# CLK2_FLAGMUX_CLK2 register map
Vendor: Texas Instruments
Peripheral module from a debugger description file (folder TDA2Ex).
Registers are 32-bit, read-only, reset values left out (the file's numbers can be read two ways) unless marked. A register's access mark holds for its fields unless they carry their own. Offsets are as the file gives them; lines under a group give offsets from that group; [hi:lo] are bit positions; {n}, {i} and the like mark numbered series; 'fields as' and 'values as' point back to an identical list; <NAME> marks a mode.

## CLK2_FLAGMUX_CLK2
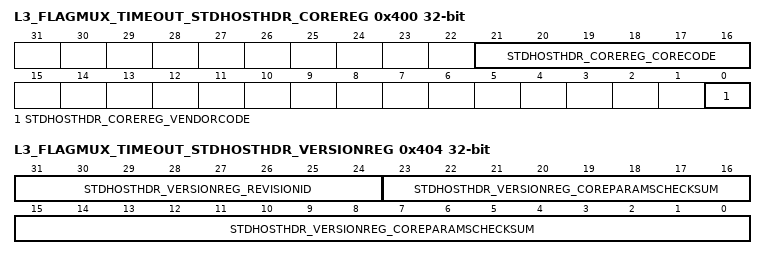
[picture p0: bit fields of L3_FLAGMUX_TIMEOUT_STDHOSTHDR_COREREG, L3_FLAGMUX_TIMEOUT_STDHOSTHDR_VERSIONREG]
0x400 L3_FLAGMUX_TIMEOUT_STDHOSTHDR_COREREG
  [21:16] STDHOSTHDR_COREREG_CORECODE — The Core Code field is a constantreporting a vendor-specific core generator code. Type: Constant. Reset value: 0x37.
  [0] STDHOSTHDR_COREREG_VENDORCODE — The Vendor Code field is a constantreporting the core generator vendor code. Type: Constant. Reset value: 0x1.
    1=ARTERIS; 0=UNDEFINED (Third-party vendor.)
0x404 L3_FLAGMUX_TIMEOUT_STDHOSTHDR_VERSIONREG
  [31:24] STDHOSTHDR_VERSIONREG_REVISIONID — The Revision Identifier field is a constantreporting the core generator revision number. Type: Constant. Reset value: 0x0.
  [23:0] STDHOSTHDR_VERSIONREG_COREPARAMSCHECKSUM — Reserved. Type: Reserved. Reset value: Reserved.
0x408 L3_FLAGMUX_TIMEOUT_MASK0 access per field
  [1:0] MASK0 rw — mask flag inputs 0 Type: Control. Reset value: 0x0.
0x40C L3_FLAGMUX_TIMEOUT_REGERR0
  [1:0] REGERR0 — flag inputs 0 Type: Status. Reset value: X.
